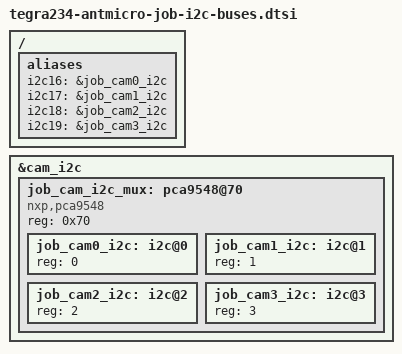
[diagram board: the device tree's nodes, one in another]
/*
 * Copyright (c) 2023 Antmicro <www.antmicro.com>
 *
 * This program is free software; you can redistribute it and/or modify
 * it under the terms of the GNU General Public License as published by
 * the Free Software Foundation; version 2 of the License.
 *
 * This program is distributed in the hope that it will be useful, but WITHOUT
 * ANY WARRANTY; without even the implied warranty of MERCHANTABILITY or
 * FITNESS FOR A PARTICULAR PURPOSE.  See the GNU General Public License for
 * more details.
 */

&cam_i2c {
	job_cam_i2c_mux: pca9548@70 {
		compatible = "nxp,pca9548";
		status = "okay";
		reg = <0x70>;
		#address-cells = <1>;
		#size-cells = <0>;

		job_cam0_i2c: i2c@0 {
			#address-cells = <1>;
			#size-cells = <0>;
			reg = <0>;
		};

		job_cam1_i2c: i2c@1 {
			#address-cells = <1>;
			#size-cells = <0>;
			reg = <1>;
		};

		job_cam2_i2c: i2c@2 {
			#address-cells = <1>;
			#size-cells = <0>;
			reg = <2>;
		};

		job_cam3_i2c: i2c@3 {
			#address-cells = <1>;
			#size-cells = <0>;
			reg = <3>;
		};
	};
};

/ {
	/*
	 * Assign fixed I2C bus numbers (visible as /dev/i2c-*)
	 * to muxed CAM I2C interfaces
	 */
	aliases {
		i2c16 = &job_cam0_i2c;
		i2c17 = &job_cam1_i2c;
		i2c18 = &job_cam2_i2c;
		i2c19 = &job_cam3_i2c;
	};
};
